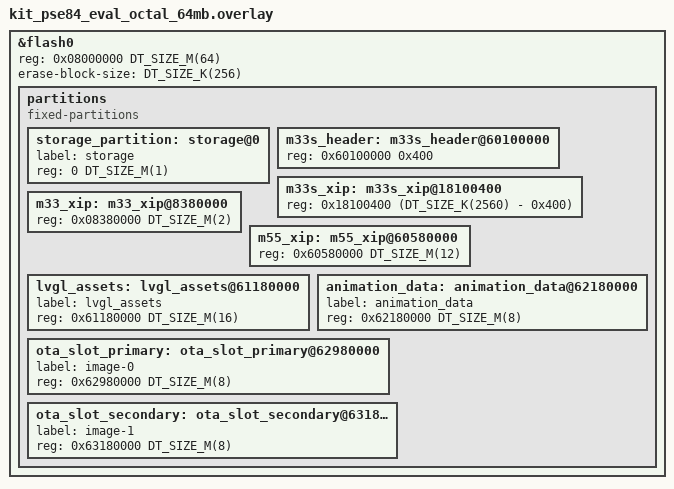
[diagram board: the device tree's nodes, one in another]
/*
 * Copyright (c) 2026 Dan Ahern
 *
 * SPDX-License-Identifier: Apache-2.0
 *
 * 64 MB Octal NOR partition layout for kit_pse84_eval.
 *
 * Replaces the stock 16 MB Quad partition table with one sized for the
 * S28HS01GT Octal NOR on CS0. Keeps the same four partition labels the
 * existing SoC / sample code uses (storage, m33s_header, m33s_xip,
 * m33_xip, m55_xip) so no C or CMake changes are needed, then adds new
 * partitions for LVGL assets, animation data, and MCUboot OTA slots in
 * the space beyond the stock 16 MB.
 *
 * Usage:
 *   Apps opt in by including this overlay from their own app-local
 *   board overlay:
 *
 *       #include <kit_pse84_eval_octal_64mb.overlay>
 *
 *   AND setting CONFIG_INFINEON_SMIF_OCTAL=y in their prj.conf AND
 *   sysbuild/enable_cm55.conf. The M33 companion's ifx_pse84_cm55_startup
 *   handles the runtime SMIF Quad -> Octal DDR transition before
 *   cy_mpc_init programs the M55 aperture.
 *
 *   Flash with the patched PSE84_SMIF.FLM (generated by the ModusToolbox
 *   QSPI Configurator CLI with the "Octal DDR Hybrid at Bottom 25 MHz"
 *   preset) by setting SMIF_OCTAL=1 and SMIF_OCTAL_FLM=/path/to/flm in
 *   the environment before west flash.
 *
 * Layout (fits within the 58 MB M55 MPC cap; see CY_XIP_PORT0_SIZE
 * boundary workaround in soc/infineon/edge/pse84/security_config/
 * pse84_s_protection.c):
 *
 *   0x60000000  storage_partition    1   MB   (unchanged, ROM lookup)
 *   0x60100000  m33s_header          1   KB   (unchanged, ROM lookup)
 *   0x60100400  m33s_xip             2.5 MB   (up from 2.25 MB)
 *   0x60380000  m33_xip              2   MB   (up from 1.79 MB)
 *   0x60580000  m55_xip             12   MB   (up from 2 MB)
 *   0x61180000  lvgl_assets         16   MB   (new)
 *   0x62180000  animation_data       8   MB   (new)
 *   0x62980000  ota_slot_primary     8   MB   (new, MCUboot)
 *   0x63180000  ota_slot_secondary   8   MB   (new, MCUboot)
 *   0x63980000  reserved             5.5 MB   (unused tail to the MPC cap)
 *
 *   End of used range: 0x63F00000 = exactly 0x03A00000 past m55_xip base
 *   (0x00500000 offset + 0x03A00000 size). Stays one MB below the
 *   0x04000000 hardware-cache boundary that trips the MPC bug.
 */

&flash0 {
	/* Bump the DT flash size from the stock 16 MB (Quad S25FS128S)
	 * to 64 MB (the Octal S28HS01GT XIP aperture on SMIF0 Port 0).
	 * The physical chip is 128 MB but only the first 64 MB is
	 * XIP-mapped; the upper 64 MB is accessible via MMIO flash API.
	 */
	reg = <0x08000000 DT_SIZE_M(64)>;
	/* S28HS01GT uniform 256 KB sectors in OPI DDR mode. */
	erase-block-size = <DT_SIZE_K(256)>;

	/delete-node/ partitions;

	partitions {
		#address-cells = <1>;
		#size-cells = <1>;
		compatible = "fixed-partitions";

		storage_partition: storage@0 {
			label = "storage";
			reg = <0 DT_SIZE_M(1)>;
		};

		m33s_header: m33s_header@60100000 {
			reg = <0x60100000 0x400>;
		};

		m33s_xip: m33s_xip@18100400 {
			reg = <0x18100400 (DT_SIZE_K(2560) - 0x400)>;
		};

		m33_xip: m33_xip@8380000 {
			reg = <0x08380000 DT_SIZE_M(2)>;
		};

		m55_xip: m55_xip@60580000 {
			reg = <0x60580000 DT_SIZE_M(12)>;
		};

		lvgl_assets: lvgl_assets@61180000 {
			label = "lvgl_assets";
			reg = <0x61180000 DT_SIZE_M(16)>;
		};

		animation_data: animation_data@62180000 {
			label = "animation_data";
			reg = <0x62180000 DT_SIZE_M(8)>;
		};

		ota_slot_primary: ota_slot_primary@62980000 {
			label = "image-0";
			reg = <0x62980000 DT_SIZE_M(8)>;
		};

		ota_slot_secondary: ota_slot_secondary@63180000 {
			label = "image-1";
			reg = <0x63180000 DT_SIZE_M(8)>;
		};
	};
};
